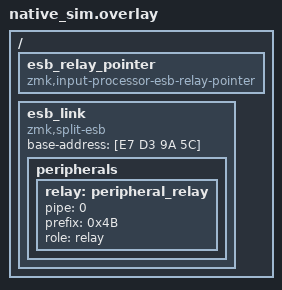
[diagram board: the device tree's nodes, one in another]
/ {
    esb_relay_pointer: esb_relay_pointer {
        compatible = "zmk,input-processor-esb-relay-pointer";
        #input-processor-cells = <0>;
    };

    esb_link {
        compatible = "zmk,split-esb";
        base-address = [E7 D3 9A 5C];

        peripherals {
            relay: peripheral_relay {
                pipe = <0>;
                prefix = <0x4B>;
                role = "relay";
            };
        };
    };
};
